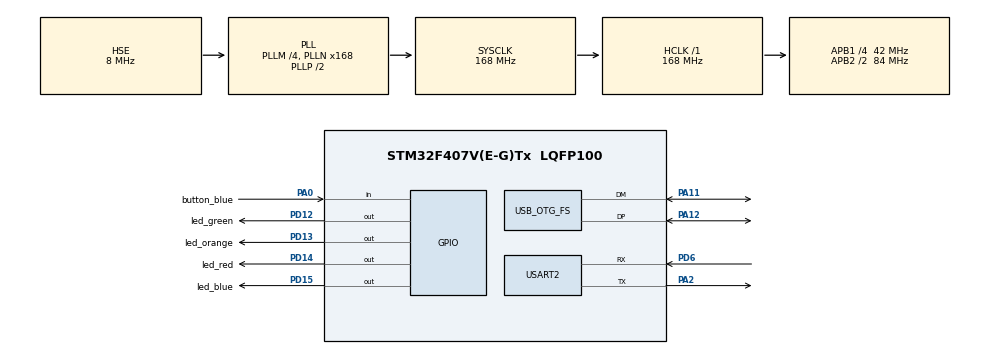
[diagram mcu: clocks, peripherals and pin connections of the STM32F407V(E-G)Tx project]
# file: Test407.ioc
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Mcu.Family=STM32F4
Mcu.Name=STM32F407V(E-G)Tx
Mcu.Package=LQFP100
NVIC.OTG_FS_IRQn=true\:0\:0\:false\:false\:true\:false\:true
NVIC.PriorityGroup=NVIC_PRIORITYGROUP_4
PA0-WKUP.GPIO_Label=button_blue
PA0-WKUP.Signal=GPIO_Input
PA11.Mode=Device_Only
PA11.Signal=USB_OTG_FS_DM
PA12.Mode=Device_Only
PA12.Signal=USB_OTG_FS_DP
PA13.Mode=Serial_Wire
PA13.Signal=SYS_JTMS-SWDIO
PA14.Mode=Serial_Wire
PA14.Signal=SYS_JTCK-SWCLK
PA2.Mode=Asynchronous
PA2.Signal=USART2_TX
PC14-OSC32_IN.Mode=LSE-External-Oscillator
PC14-OSC32_IN.Signal=RCC_OSC32_IN
PC15-OSC32_OUT.Mode=LSE-External-Oscillator
PC15-OSC32_OUT.Signal=RCC_OSC32_OUT
PD12.GPIO_Label=led_green
PD12.Signal=GPIO_Output
PD13.GPIO_Label=led_orange
PD13.Signal=GPIO_Output
PD14.GPIO_Label=led_red
PD14.Signal=GPIO_Output
PD15.GPIO_Label=led_blue
PD15.Signal=GPIO_Output
PD6.Mode=Asynchronous
PD6.Signal=USART2_RX
PH0-OSC_IN.Mode=HSE-External-Oscillator
PH0-OSC_IN.Signal=RCC_OSC_IN
PH1-OSC_OUT.Mode=HSE-External-Oscillator
PH1-OSC_OUT.Signal=RCC_OSC_OUT
ProjectManager.HeapSize=0x200
ProjectManager.StackSize=0x400
ProjectManager.TargetToolchain=STM32CubeIDE
RCC.48MHZClocksFreq_Value=48000000
RCC.AHBFreq_Value=168000000
RCC.APB1CLKDivider=RCC_HCLK_DIV4
RCC.APB1Freq_Value=42000000
RCC.APB1TimFreq_Value=84000000
RCC.APB2CLKDivider=RCC_HCLK_DIV2
RCC.APB2Freq_Value=84000000
RCC.APB2TimFreq_Value=168000000
RCC.CortexFreq_Value=168000000
RCC.HCLKFreq_Value=168000000
RCC.HSE_VALUE=8000000
RCC.HSI_VALUE=16000000
RCC.PLLM=4
RCC.PLLN=168
RCC.PLLQ=7
RCC.SYSCLKFreq_VALUE=168000000
RCC.SYSCLKSource=RCC_SYSCLKSOURCE_PLLCLK
RCC.VCOOutputFreq_Value=336000000
USART2.VirtualMode=VM_ASYNC
USB_DEVICE.CLASS_NAME_FS=CDC
USB_DEVICE.VirtualMode-CDC_FS=Cdc
USB_DEVICE.VirtualModeFS=Cdc_FS
USB_OTG_FS.VirtualMode=Device_Only
VP_USB_DEVICE_VS_USB_DEVICE_CDC_FS.Mode=CDC_FS
board=custom

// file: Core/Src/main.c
/* USER CODE BEGIN Header */
/**
  ******************************************************************************
  * @file           : main.c
  * @brief          : Main program body
  ******************************************************************************
  * @attention
  *
  * <h2><center>&copy; Copyright (c) 2020 STMicroelectronics.
  * All rights reserved.</center></h2>
  *
  * This software component is licensed by ST under BSD 3-Clause license,
  * the "License"; You may not use this file except in compliance with the
  * License. You may obtain a copy of the License at:
  *                        opensource.org/licenses/BSD-3-Clause
  *
  ******************************************************************************
  */
/* USER CODE END Header */

#include "main.h"
#include "usb_device.h"

/* USER CODE BEGIN Includes */
#include "usbd_cdc_if.h"
/* USER CODE END Includes */

/* USER CODE BEGIN PD */
//#include "define_EdGull.h"
#define Delay HAL_Delay
#define Toggle HAL_GPIO_TogglePin
#define led_green led_green_GPIO_Port,led_green_Pin
#define led_red led_red_GPIO_Port,led_red_Pin
#define led_blue led_blue_GPIO_Port,led_blue_Pin
#define led_orange led_orange_GPIO_Port,led_orange_Pin

/* USER CODE END PD */

UART_HandleTypeDef huart2;

void SystemClock_Config(void);
static void MX_GPIO_Init(void);
static void MX_USART2_UART_Init(void);

int main(void)
{
  /* USER CODE BEGIN 1 */
	char str_tx[21];
  	sprintf(str_tx,"Start LoRaPhone\r\n");
  /* USER CODE END 1 */

  /* MCU Configuration--------------------------------------------------------*/

  /* Reset of all peripherals, Initializes the Flash interface and the Systick. */
  HAL_Init();

  /* Configure the system clock */
  SystemClock_Config();

  /* Initialize all configured peripherals */
  MX_GPIO_Init();
  MX_USART2_UART_Init();
  MX_USB_DEVICE_Init();

  /* Infinite loop */
  while (1)
  {
//#include "main_EdGull.c"
	  	  Delay (500);
	  	  Toggle(led_red);
	  	  Toggle(led_green);
	  	  Toggle(led_blue);
	  	  Toggle(led_orange);
	  	  CDC_Transmit_FS((unsigned char*)str_tx, strlen(str_tx));

  }
}

void SystemClock_Config(void)
{
  RCC_OscInitTypeDef RCC_OscInitStruct = {0};
  RCC_ClkInitTypeDef RCC_ClkInitStruct = {0};

  /** Configure the main internal regulator output voltage
  */
  __HAL_RCC_PWR_CLK_ENABLE();
  __HAL_PWR_VOLTAGESCALING_CONFIG(PWR_REGULATOR_VOLTAGE_SCALE1);
  /** Initializes the CPU, AHB and APB busses clocks
  */
  RCC_OscInitStruct.OscillatorType = RCC_OSCILLATORTYPE_HSE;
  RCC_OscInitStruct.HSEState = RCC_HSE_ON;
  RCC_OscInitStruct.PLL.PLLState = RCC_PLL_ON;
  RCC_OscInitStruct.PLL.PLLSource = RCC_PLLSOURCE_HSE;
  RCC_OscInitStruct.PLL.PLLM = 4;
  RCC_OscInitStruct.PLL.PLLN = 168;
  RCC_OscInitStruct.PLL.PLLP = RCC_PLLP_DIV2;
  RCC_OscInitStruct.PLL.PLLQ = 7;
  if (HAL_RCC_OscConfig(&RCC_OscInitStruct) != HAL_OK)
  {
    Error_Handler();
  }
  /** Initializes the CPU, AHB and APB busses clocks
  */
  RCC_ClkInitStruct.ClockType = RCC_CLOCKTYPE_HCLK|RCC_CLOCKTYPE_SYSCLK
                              |RCC_CLOCKTYPE_PCLK1|RCC_CLOCKTYPE_PCLK2;
  RCC_ClkInitStruct.SYSCLKSource = RCC_SYSCLKSOURCE_PLLCLK;
  RCC_ClkInitStruct.AHBCLKDivider = RCC_SYSCLK_DIV1;
  RCC_ClkInitStruct.APB1CLKDivider = RCC_HCLK_DIV4;
  RCC_ClkInitStruct.APB2CLKDivider = RCC_HCLK_DIV2;

  if (HAL_RCC_ClockConfig(&RCC_ClkInitStruct, FLASH_LATENCY_5) != HAL_OK)
  {
    Error_Handler();
  }
}

static void MX_USART2_UART_Init(void)
{

  huart2.Instance = USART2;
  huart2.Init.BaudRate = 115200;
  huart2.Init.WordLength = UART_WORDLENGTH_8B;
  huart2.Init.StopBits = UART_STOPBITS_1;
  huart2.Init.Parity = UART_PARITY_NONE;
  huart2.Init.Mode = UART_MODE_TX_RX;
  huart2.Init.HwFlowCtl = UART_HWCONTROL_NONE;
  huart2.Init.OverSampling = UART_OVERSAMPLING_16;
  if (HAL_UART_Init(&huart2) != HAL_OK)
  {
    Error_Handler();
  }

}

static void MX_GPIO_Init(void)
{
  GPIO_InitTypeDef GPIO_InitStruct = {0};

  /* GPIO Ports Clock Enable */
  __HAL_RCC_GPIOC_CLK_ENABLE();
  __HAL_RCC_GPIOH_CLK_ENABLE();
  __HAL_RCC_GPIOA_CLK_ENABLE();
  __HAL_RCC_GPIOD_CLK_ENABLE();

  /*Configure GPIO pin Output Level */
  HAL_GPIO_WritePin(GPIOD, led_green_Pin|led_orange_Pin|led_red_Pin|led_blue_Pin, GPIO_PIN_RESET);

  /*Configure GPIO pin : button_blue_Pin */
  GPIO_InitStruct.Pin = button_blue_Pin;
  GPIO_InitStruct.Mode = GPIO_MODE_INPUT;
  GPIO_InitStruct.Pull = GPIO_NOPULL;
  HAL_GPIO_Init(button_blue_GPIO_Port, &GPIO_InitStruct);

  /*Configure GPIO pins : led_green_Pin led_orange_Pin led_red_Pin led_blue_Pin */
  GPIO_InitStruct.Pin = led_green_Pin|led_orange_Pin|led_red_Pin|led_blue_Pin;
  GPIO_InitStruct.Mode = GPIO_MODE_OUTPUT_PP;
  GPIO_InitStruct.Pull = GPIO_NOPULL;
  GPIO_InitStruct.Speed = GPIO_SPEED_FREQ_LOW;
  HAL_GPIO_Init(GPIOD, &GPIO_InitStruct);

}

void Error_Handler(void)
{
}

/************************ (C) COPYRIGHT STMicroelectronics *****END OF FILE****/
